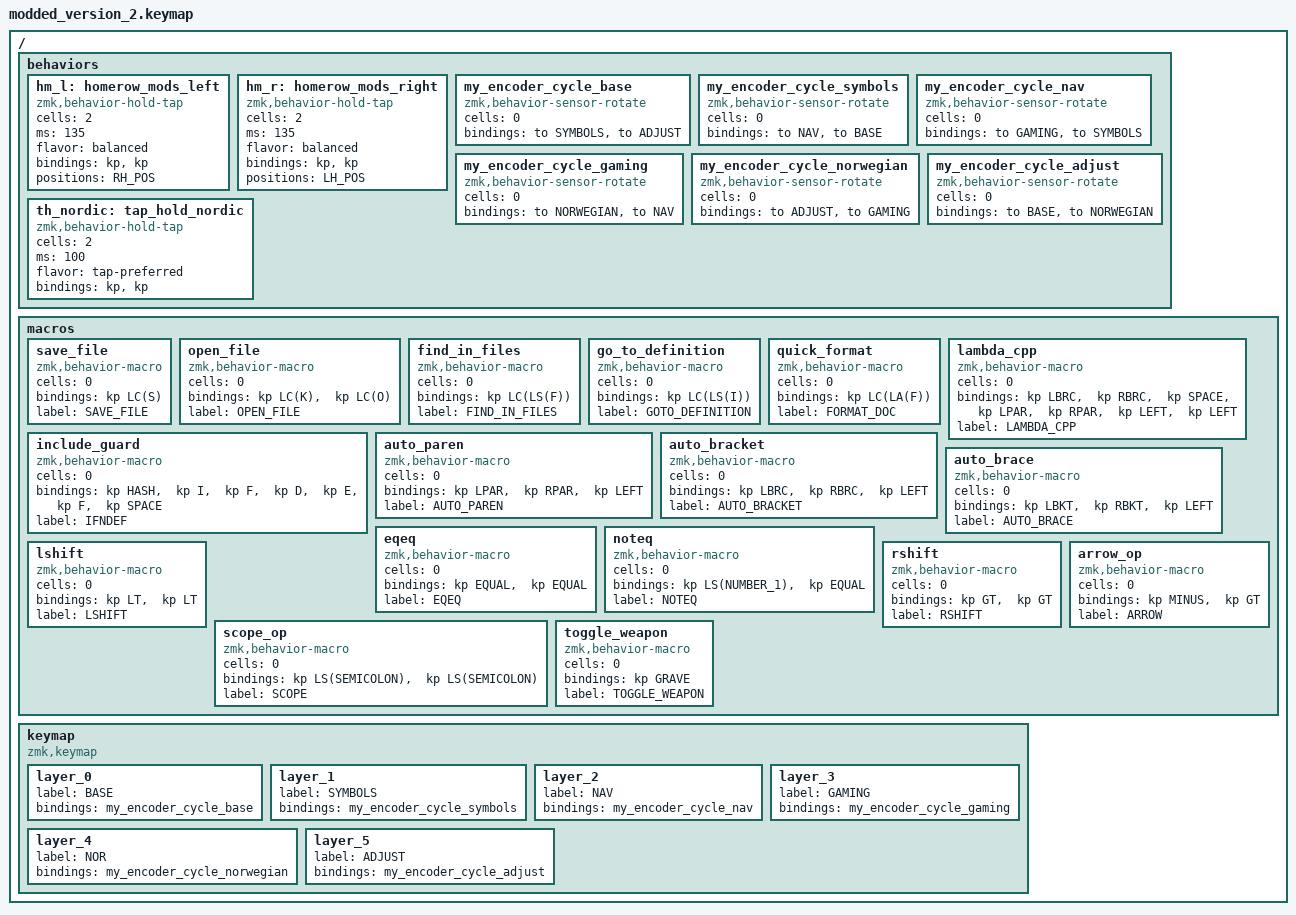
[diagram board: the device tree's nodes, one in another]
// Sofle Ergomech - Programmer-Optimized Keymap
// Target: C/C++, Python, Rust + Norwegian typing

#include <behaviors.dtsi>
#include <dt-bindings/zmk/keys.h>
#include <dt-bindings/zmk/bt.h>
#include <dt-bindings/zmk/ext_power.h>
#include <dt-bindings/zmk/rgb.h>

#define BASE 0
#define SYMBOLS 1
#define NAV 2
#define GAMING 3
#define NORWEGIAN 4
#define ADJUST 5

#define NO_AE SE_AE
#define NO_O_SLASH SE_O
#define NO_AA SE_AA

// Left/Right side key position masks for structural rollover blocking
#define LH_POS 0 1 2 3 4 5 12 13 14 15 16 17 24 25 26 27 28 29 36 37 38 39 40 41 48 49 50 51 52 53 54 55 56 57 58 59 60 61 62 63
#define RH_POS 6 7 8 9 10 11 18 19 20 21 22 23 30 31 32 33 34 35 42 43 44 45 46 47 48 49 50 51 52 53 54 55 56 57 58 59 60 61 62 63

/
{
    behaviors
    {
    hm_l:
        homerow_mods_left
        {
            compatible = "zmk,behavior-hold-tap";
#binding - cells = < 2>;
            tapping - term - ms = <200>;
            quick - tap - ms = <135>;
            flavor = "balanced";
            bindings = <&kp>, <&kp>;
            hold - trigger - key - positions = <RH_POS>;
        };

    hm_r:
        homerow_mods_right
        {
            compatible = "zmk,behavior-hold-tap";
#binding - cells = < 2>;
            tapping - term - ms = <200>;
            quick - tap - ms = <135>;
            flavor = "balanced";
            bindings = <&kp>, <&kp>;
            hold - trigger - key - positions = <LH_POS>;
        };

    my_encoder_cycle_base:
        my_encoder_cycle_base
        {
            compatible = "zmk,behavior-sensor-rotate";
#sensor - binding - cells = < 0>;
            bindings = <&to SYMBOLS>, <&to ADJUST>;
        };

    my_encoder_cycle_symbols:
        my_encoder_cycle_symbols
        {
            compatible = "zmk,behavior-sensor-rotate";
#sensor - binding - cells = < 0>;
            bindings = <&to NAV>, <&to BASE>;
        };

    my_encoder_cycle_nav:
        my_encoder_cycle_nav
        {
            compatible = "zmk,behavior-sensor-rotate";
#sensor - binding - cells = < 0>;
            bindings = <&to GAMING>, <&to SYMBOLS>;
        };

    my_encoder_cycle_gaming:
        my_encoder_cycle_gaming
        {
            compatible = "zmk,behavior-sensor-rotate";
#sensor - binding - cells = < 0>;
            bindings = <&to NORWEGIAN>, <&to NAV>;
        };

    my_encoder_cycle_norwegian:
        my_encoder_cycle_norwegian
        {
            compatible = "zmk,behavior-sensor-rotate";
#sensor - binding - cells = < 0>;
            bindings = <&to ADJUST>, <&to GAMING>;
        };

    my_encoder_cycle_adjust:
        my_encoder_cycle_adjust
        {
            compatible = "zmk,behavior-sensor-rotate";
#sensor - binding - cells = < 0>;
            bindings = <&to BASE>, <&to NORWEGIAN>;
        };

    th_nordic:
        tap_hold_nordic
        {
            compatible = "zmk,behavior-hold-tap";
#binding - cells = < 2>;
            tapping - term - ms = <150>;
            quick - tap - ms = <100>;
            flavor = "tap-preferred";
            bindings = <&kp>, <&kp>;
        };
    };

    macros
    {
    save_file:
        save_file
        {
            compatible = "zmk,behavior-macro";
#binding - cells = < 0>;
            bindings = <&kp LC(S)>;
            label = "SAVE_FILE";
        };
    open_file:
        open_file
        {
            compatible = "zmk,behavior-macro";
#binding - cells = < 0>;
            bindings = <&kp LC(K) & kp LC(O)>;
            label = "OPEN_FILE";
        };
    find_in_files:
        find_in_files
        {
            compatible = "zmk,behavior-macro";
#binding - cells = < 0>;
            bindings = <&kp LC(LS(F))>;
            label = "FIND_IN_FILES";
        };
    go_to_definition:
        go_to_definition
        {
            compatible = "zmk,behavior-macro";
#binding - cells = < 0>;
            bindings = <&kp LC(LS(I))>;
            label = "GOTO_DEFINITION";
        };
    quick_format:
        quick_format
        {
            compatible = "zmk,behavior-macro";
#binding - cells = < 0>;
            bindings = <&kp LC(LA(F))>;
            label = "FORMAT_DOC";
        };
    include_guard:
        include_guard
        {
            compatible = "zmk,behavior-macro";
#binding - cells = < 0>;
            bindings = <&kp HASH & kp I & kp F & kp D & kp E & kp F & kp SPACE>;
            label = "IFNDEF";
        };
    lambda_cpp:
        lambda_cpp
        {
            compatible = "zmk,behavior-macro";
#binding - cells = < 0>;
            bindings = <&kp LBRC & kp RBRC & kp SPACE & kp LPAR & kp RPAR & kp LEFT & kp LEFT>;
            label = "LAMBDA_CPP";
        };
    auto_paren:
        auto_paren
        {
            compatible = "zmk,behavior-macro";
#binding - cells = < 0>;
            bindings = <&kp LPAR & kp RPAR & kp LEFT>;
            label = "AUTO_PAREN";
        };
    auto_bracket:
        auto_bracket
        {
            compatible = "zmk,behavior-macro";
#binding - cells = < 0>;
            bindings = <&kp LBRC & kp RBRC & kp LEFT>;
            label = "AUTO_BRACKET";
        };
    auto_brace:
        auto_brace
        {
            compatible = "zmk,behavior-macro";
#binding - cells = < 0>;
            bindings = <&kp LBKT & kp RBKT & kp LEFT>;
            label = "AUTO_BRACE";
        };
    eqeq:
        eqeq
        {
            compatible = "zmk,behavior-macro";
#binding - cells = < 0>;
            bindings = <&kp EQUAL & kp EQUAL>;
            label = "EQEQ";
        };
    noteq:
        noteq
        {
            compatible = "zmk,behavior-macro";
#binding - cells = < 0>;
            bindings = <&kp LS(NUMBER_1) & kp EQUAL>;
            label = "NOTEQ";
        };
    lshift:
        lshift
        {
            compatible = "zmk,behavior-macro";
#binding - cells = < 0>;
            bindings = <&kp LT & kp LT>;
            label = "LSHIFT";
        };
    rshift:
        rshift
        {
            compatible = "zmk,behavior-macro";
#binding - cells = < 0>;
            bindings = <&kp GT & kp GT>;
            label = "RSHIFT";
        };
    scope_op:
        scope_op
        {
            compatible = "zmk,behavior-macro";
#binding - cells = < 0>;
            bindings = <&kp LS(SEMICOLON) & kp LS(SEMICOLON)>;
            label = "SCOPE";
        };
    arrow_op:
        arrow_op
        {
            compatible = "zmk,behavior-macro";
#binding - cells = < 0>;
            bindings = <&kp MINUS & kp GT>;
            label = "ARROW";
        };
    toggle_weapon:
        toggle_weapon
        {
            compatible = "zmk,behavior-macro";
#binding - cells = < 0>;
            bindings = <&kp GRAVE>;
            label = "TOGGLE_WEAPON";
        };
    };

    keymap
    {
        compatible = "zmk,keymap";

        layer_0
        {
            label = "BASE";
            bindings = <
                &kp ESCAPE & kp N1 & kp N2 & kp N3 & kp N4 & kp N5 & kp N6 & kp N7 & kp N8 & kp N9 & kp N0 & kp MINUS & kp TAB & kp Q & kp W & kp E & kp R & kp T & kp Y & kp U & kp I & kp O & kp P & kp BSLH & kp LSHFT & hm_l LGUI A & hm_l LALT S & hm_l LCTRL D & hm_l LSHIFT F & kp G & kp H & hm_r RSHIFT J & hm_r RCTRL K & hm_r RALT L & hm_r RGUI SEMI & kp SQT & kp LCTRL & kp Z & kp X & kp C & kp V & kp B & kp C_MUTE & none & kp N & kp M & kp COMMA & kp DOT & kp FSLH & kp RSHFT & kp LGUI & kp LALT & kp RETURN & kp SPACE & mo SYMBOLS & mo NAV & kp SPACE & mo NORWEGIAN & kp RCTRL & kp C_PLAY_PAUSE & kp RIGHT_ARROW & kp UP_ARROW & kp LEFT_ARROW & kp DOWN_ARROW>;
            sensor - bindings = <&my_encoder_cycle_base>;
        };

        layer_1
        {
            label = "SYMBOLS";
            bindings = <
                &trans & kp F1 & kp F2 & kp F3 & kp F4 & kp F5 & kp F6 & kp F7 & kp F8 & kp F9 & kp F10 & kp F11 & trans & kp EXCL & kp LT & kp GT & kp EQUAL & kp DLLR & kp AMPS & auto_brace & kp RBKT & kp BSLH & kp PRCNT & kp F12 & trans & kp GRAVE & kp MINUS & kp PLUS & kp ASTRK & kp COLON & scope_op & auto_paren & kp RPAR & kp PIPE & kp QMARK & kp PIPE & trans & kp TILDE & kp UNDER & kp FSLH & kp POUND & eqeq & trans & trans & arrow_op & auto_bracket & kp RBRC & kp AT & kp CARET & trans & trans & trans & trans & trans & trans & trans & trans & trans & trans & trans

                // 5-Way Switch Directional Cluster
                & kp C_PLAY_PAUSE & kp RIGHT_ARROW & kp UP_ARROW & kp LEFT_ARROW & kp DOWN_ARROW>;
            sensor - bindings = <&my_encoder_cycle_symbols>;
        };

        layer_2
        {
            label = "NAV";
            bindings = <
                &trans & trans & trans & trans & trans & trans & trans & trans & trans & trans & trans & trans & trans & save_file & open_file & find_in_files & go_to_definition & quick_format & kp HOME & kp PGDN & kp PGUP & kp END & kp DEL & trans & trans & kp LGUI & kp LALT & kp LCTRL & kp LSHIFT & trans & kp LEFT & kp DOWN & kp UP & kp RIGHT & kp BSPC & trans & trans & trans & trans & trans & trans & trans & trans & trans & trans & trans & trans & trans & trans & trans & trans & trans & trans & trans & trans & trans & trans & trans & trans & trans & kp C_PLAY_PAUSE & kp RIGHT_ARROW & kp UP_ARROW & kp LEFT_ARROW & kp DOWN_ARROW>;
            sensor - bindings = <&my_encoder_cycle_nav>;
        };

        layer_3
        {
            label = "GAMING";
            bindings = <
                &kp ESC & kp N1 & kp N2 & kp N3 & kp N4 & kp N5 & trans & trans & trans & trans & trans & trans & kp TAB & kp Q & kp W & kp E & kp R & kp T & trans & trans & trans & trans & trans & trans & kp LSHFT & kp A & kp S & kp D & kp F & kp G & trans & trans & trans & trans & trans & trans & kp LCTRL & kp Z & kp X & kp C & kp V & kp B & toggle_weapon & trans & trans & trans & trans & trans & trans & trans & trans & trans & trans & kp SPACE & trans & trans & trans & trans & trans & trans & kp C_PLAY_PAUSE & kp RIGHT_ARROW & kp UP_ARROW & kp LEFT_ARROW & kp DOWN_ARROW>;
            sensor - bindings = <&my_encoder_cycle_gaming>;
        };

        layer_4
        {
            label = "NOR";
            bindings = <
                &trans & trans & trans & trans & trans & trans & trans & trans & trans & trans & trans & trans & trans & trans & trans & trans & trans & trans & trans & trans & trans & trans & trans & trans & trans & th_nordic NO_AA A & trans & trans & trans & trans & trans & trans & trans & trans & trans & trans & trans & trans & trans & trans & trans & trans & trans & trans & trans & trans & trans & trans & trans & trans & trans & trans & trans & trans & trans & trans & trans & trans & trans & trans & kp C_PLAY_PAUSE & kp RIGHT_ARROW & kp UP_ARROW & kp LEFT_ARROW & kp DOWN_ARROW>;
            sensor - bindings = <&my_encoder_cycle_norwegian>;
        };

        layer_5
        {
            label = "ADJUST";
            bindings = <
                &bt BT_CLR & bt BT_SEL 0 & bt BT_SEL 1 & bt BT_SEL 2 & bt BT_SEL 3 & bt BT_SEL 4 & trans & trans & trans & trans & trans & trans & ext_power EP_TOG & rgb_ug RGB_HUD & rgb_ug RGB_HUI & rgb_ug RGB_SAD & rgb_ug RGB_SAI & rgb_ug RGB_EFF & trans & trans & trans & trans & trans & trans & trans & trans & rgb_ug RGB_BRI & trans & trans & trans & trans & trans & trans & trans & trans & trans & trans & trans & trans & trans & trans & trans & rgb_ug RGB_TOG & trans & trans & trans & trans & trans & trans & trans & trans & trans & trans & trans & trans & trans & trans & trans & trans & trans & kp C_PLAY_PAUSE & kp RIGHT_ARROW & kp UP_ARROW & kp LEFT_ARROW & kp DOWN_ARROW>;
            sensor - bindings = <&my_encoder_cycle_adjust>;
        };
    };
};
